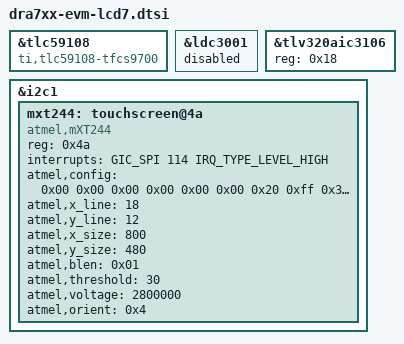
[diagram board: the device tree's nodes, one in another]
/*
 * Copyright (C) 2013 Texas Instruments Incorporated - http://www.ti.com/
 *
 * This program is free software; you can redistribute it and/or modify
 * it under the terms of the GNU General Public License version 2 as
 * published by the Free Software Foundation.
 */

#include "dra7xx-evm-lcd10.dtsi"

&tlc59108 {
	compatible = "ti,tlc59108-tfcs9700";
};

&ldc3001 {
	status = "disabled";
};

&tlv320aic3106 {
      reg = <0x18>;
};

&i2c1 {
	mxt244: touchscreen@4a {
		compatible = "atmel,mXT244";
		status = "okay";
		reg = <0x4a>;
		interrupts = <GIC_SPI 114 IRQ_TYPE_LEVEL_HIGH>;

		atmel,config = <
			/* MXT244_GEN_COMMAND(6) */
			0x00 0x00 0x00 0x00 0x00 0x00
			/* MXT244_GEN_POWER(7) */
			0x20 0xff 0x32
			/* MXT244_GEN_ACQUIRE(8) */
			0x0a 0x00 0x05 0x00 0x00 0x00 0x09 0x23
			/* MXT244_TOUCH_MULTI(9) */
			0x00 0x00 0x00 0x13 0x0b 0x00 0x00 0x00 0x02 0x00
			0x00 0x01 0x01 0x0e 0x0a 0x0a 0x0a 0x0a 0x00 0x00
			0x00 0x00 0x00 0x00 0x00 0x00 0x00 0x00 0x00 0x00
			0x00
			/* MXT244_TOUCH_KEYARRAY(15) */
			0x00 0x00 0x00 0x00 0x00 0x00 0x00 0x00 0x00 0x00
			0x00
			/* MXT244_COMMSCONFIG_T18(2) */
			0x00 0x00
			/* MXT244_SPT_GPIOPWM(19) */
			0x00 0x00 0x00 0x00 0x00 0x00 0x00 0x00 0x00 0x00
			0x00 0x00 0x00 0x00 0x00 0x00
			/* MXT244_PROCI_GRIPFACE(20) */
			0x07 0x00 0x00 0x00 0x00 0x00 0x00 0x50 0x28 0x04
			0x0f 0x0a
			/* MXT244_PROCG_NOISE(22) */
			0x05 0x00 0x00 0x00 0x00 0x00 0x00 0x03 0x23 0x00
			0x00 0x05 0x0f 0x19 0x23 0x2d 0x03
			/* MXT244_TOUCH_PROXIMITY(23) */
			0x00 0x00 0x00 0x00 0x00 0x00 0x00 0x00 0x00 0x00
			0x00 0x00 0x00 0x00 0x00
			/* MXT244_PROCI_ONETOUCH(24) */
			0x00 0x00 0x00 0x00 0x00 0x00 0x00 0x00 0x00 0x00
			0x00 0x00 0x00 0x00 0x00 0x00 0x00 0x00 0x00
			/* MXT244_SPT_SELFTEST(25) */
			0x00 0x00 0x00 0x00 0x00 0x00 0x00 0x00 0x00 0x00
			0x00 0x00 0x00 0x00
			/* MXT244_PROCI_TWOTOUCH(27) */
			0x00 0x00 0x00 0x00 0x00 0x00 0x00
			/* MXT244_SPT_CTECONFIG(28) */
			0x00 0x00 0x02 0x08 0x10 0x00
		>;

		atmel,x_line = <18>;
		atmel,y_line = <12>;
		atmel,x_size = <800>;
		atmel,y_size = <480>;
		atmel,blen = <0x01>;
		atmel,threshold = <30>;
		atmel,voltage = <2800000>;
		atmel,orient = <0x4>;
	};
};
